# ATmega1284RFR2 device description
Architecture: AVR8; Family: megaAVR
Registers are 8-bit, access not given, no defined reset value unless marked. A register's access mark holds for its fields unless they carry their own. Offsets are from the block's base; [hi:lo] are bit positions; {n}, {i} and the like mark numbered series; <NAME> marks a mode.

## TRX24 — Low-Power 2.4 GHz Transceiver
Instances: TRX24 0x00
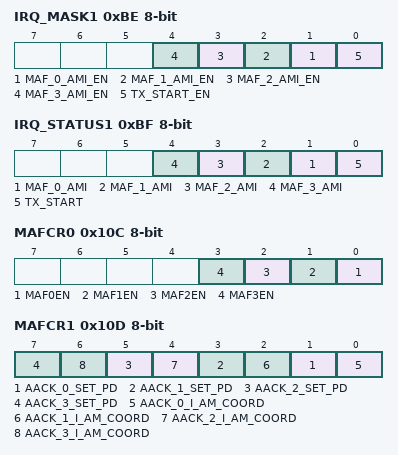
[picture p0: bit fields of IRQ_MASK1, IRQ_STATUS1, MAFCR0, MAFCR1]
0xBE IRQ_MASK1 — Transceiver Interrupt Enable Register 1
  [n+1] MAF_{n}_AMI_EN (n=0..3) — Address Match Interrupt enable Address filter {n}
  [0] TX_START_EN — Transmit Start Interrupt enable
0xBF IRQ_STATUS1 — Transceiver Interrupt Status Register 1
  [n+1] MAF_{n}_AMI (n=0..3) — Address Match Interrupt Status Address filter {n}
  [0] TX_START — Transmit Start Interrupt Status
0x10C MAFCR0 — Multiple Address Filter Configuration Register 0
  [n] MAF{n}EN (n=0..3) — Multiple Address Filter {n} Enable
0x10D MAFCR1 — Multiple Address Filter Configuration Register 1
  [2n+1] AACK_{n}_SET_PD (n=0..3) — Set Data Pending bit for address filter {n}.
  [2n] AACK_{n}_I_AM_COORD (n=0..3) — Enable PAN Coordinator mode for address filter {n}.
{0x10E+4i} MAFSA{i}L (i=0..3) — Transceiver MAC Short Address Register for Frame Filter {i} (Low Byte)
  [7:0] MAFSA{i}L — MAC Short Address low Byte for Frame Filter {i}
{0x10F+4i} MAFSA{i}H (i=0..3) — Transceiver MAC Short Address Register for Frame Filter {i} (High Byte)
  [7:0] MAFSA{i}H — MAC Short Address high Byte for Frame Filter {i}
{0x110+4i} MAFPA{i}L (i=0..3) — Transceiver Personal Area Network ID Register for Frame Filter {i} (Low Byte)
  [7:0] MAFPA{i}L — MAC Personal Area Network ID low Byte for Frame Filter {i}
{0x111+4i} MAFPA{i}H (i=0..3) — Transceiver Personal Area Network ID Register for Frame Filter {i} (High Byte)
  [7:0] MAFPA{i}H — MAC Personal Area Network ID high Byte for Frame Filter {i}
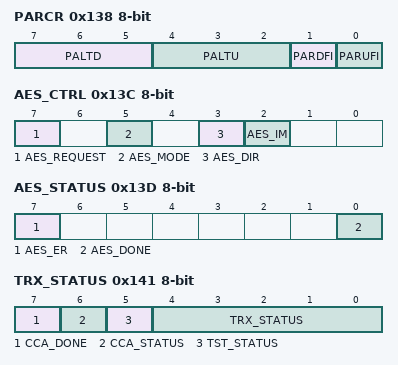
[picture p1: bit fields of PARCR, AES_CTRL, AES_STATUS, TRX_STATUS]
0x138 PARCR — Power Amplifier Ramp up/down Control Register
  [7:5] PALTD — ext. PA Ramp Down Lead Time
    0=PALTD_MINUS_3US (-3us); 1=PALTD_MINUS_2US (-2us); 2=PALTD_MINUS_1US (-1us); {v}=PALTD_{v-3}US ({v-3}us) (v=3..7)
  [4:2] PALTU — ext. PA Ramp Up Lead Time
    0=PALTU_MINUS_3US (-3us); 1=PALTU_MINUS_2US (-2us); 2=PALTU_MINUS_1US (-1us); {v}=PALTU_{v-3}US ({v-3}us) (v=3..7)
  [1] PARDFI — Power Amplifier Ramp Down Frequency Inversion
  [0] PARUFI — Power Amplifier Ramp Up Frequency Inversion
0x13C AES_CTRL — AES Control Register
  [7] AES_REQUEST — Request AES Operation.
  [5] AES_MODE — Set AES Operation Mode
    0=AES_MODE_ECB (AES Mode is ECB (Electronic Code Book).); 1=AES_MODE_CBC (AES Mode is CBC (Cipher Block Chaining).)
  [3] AES_DIR — Set AES Operation Direction
    0=AES_DIR_ENC (AES operation is encryption.); 1=AES_DIR_DEC (AES operation is decryption.)
  [2] AES_IM — AES Interrupt Enable
0x13D AES_STATUS
  [7] AES_ER — AES Operation Finished with Error
  [0] AES_DONE — AES Operation Finished with Success
0x13E AES_STATE — AES Plain and Cipher Text Buffer Register
  [7:0] AES_STATE — AES Plain and Cipher Text Buffer
0x13F AES_KEY — AES Encryption and Decryption Key Buffer Register
  [7:0] AES_KEY — AES Encryption/Decryption Key Buffer
0x141 TRX_STATUS — Transceiver Status Register
  [7] CCA_DONE — CCA Algorithm Status
    0=CCA_NOT_FIN (CCA calculation not finished); 1=CCA_FIN (CCA calculation finished)
  [6] CCA_STATUS — CCA Status Result
    0=CCA_BUSY (Channel indicated as busy.); 1=CCA_IDLE (Channel indicated as idle.)
  [5] TST_STATUS — Test mode status
    0=TST_DISABLED (Test mode is disabled.); 1=TST_ENABLED (Test mode is active.)
  [4:0] TRX_STATUS — Transceiver Main Status
    0=P_ON; 1=BUSY_RX; 2=BUSY_TX; 6=RX_ON; 8=TRX_OFF; 9=PLL_ON; 15=SLEEP; 17=BUSY_RX_AACK; 18=BUSY_TX_ARET; 22=RX_AACK_ON; 25=TX_ARET_ON; 31=STATE_TRANSITION_IN_PROGRESS
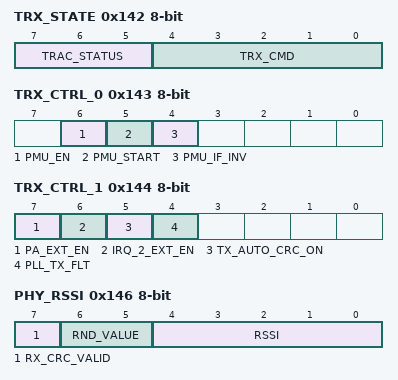
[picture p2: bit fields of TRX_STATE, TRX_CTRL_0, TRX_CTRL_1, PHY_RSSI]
0x142 TRX_STATE — Transceiver State Control Register
  [7:5] TRAC_STATUS — Transaction Status
    0=TRAC_SUCCESS (SUCCESS (RX_AACK, TX_ARET)); 1=TRAC_SUCCESS_DATA_PENDING (SUCCESS_DATA_PENDING (TX_ARET)); 2=TRAC_SUCCESS_WAIT_FOR_ACK (SUCCESS_WAIT_FOR_ACK (RX_AACK)); 3=TRAC_CHANNEL_ACCESS_FAILURE (CHANNEL_ACCESS_FAILURE (TX_ARET)); 5=TRAC_NO_ACK (NO_ACK (TX_ARET)); 7=TRAC_INVALID (INVALID (RX_AACK, TX_ARET))
  [4:0] TRX_CMD — State Control Command
    0=CMD_NOP (NOP); 2=CMD_TX_START (TX_START); 3=CMD_FORCE_TRX_OFF (FORCE_TRX_OFF); 4=CMD_FORCE_PLL_ON (FORCE_PLL_ON); 6=CMD_RX_ON (RX_ON); 8=CMD_TRX_OFF (TRX_OFF); 9=CMD_PLL_ON (PLL_ON (TX_ON)); 22=CMD_RX_AACK_ON (RX_AACK_ON); 25=CMD_TX_ARET_ON (TX_ARET_ON)
0x143 TRX_CTRL_0 — Reserved
  [6] PMU_EN — Enable Phase Measurement Unit
  [5] PMU_START — Start of Phase Measurement Unit
  [4] PMU_IF_INV — PMU IF Inverse
0x144 TRX_CTRL_1 — Transceiver Control Register 1
  [7] PA_EXT_EN — External PA support enable
  [6] IRQ_2_EXT_EN — Connect Frame Start IRQ to TC1
  [5] TX_AUTO_CRC_ON — Enable Automatic CRC Calculation
  [4] PLL_TX_FLT — Enable PLL TX filter
0x145 PHY_TX_PWR — Transceiver Transmit Power Control Register
  [3:0] TX_PWR — Transmit Power Setting
    0=3.5 dBm; 1=3.3 dBm; 2=2.8 dBm; 3=2.3 dBm; 4=1.8 dBm; 5=1.2 dBm; 6=0.5 dBm; 7=-0.5 dBm; 8=-1.5 dBm; 9=-2.5 dBm; 10=-3.5 dBm; 11=-4.5 dBm; 12=-6.5 dBm; 13=-8.5 dBm; 14=-11.5 dBm; 15=-16.5 dBm
0x146 PHY_RSSI — Receiver Signal Strength Indicator Register
  [7] RX_CRC_VALID — Received Frame CRC Status
    0=CRC_INVALID (CRC (FCS) not valid); 1=CRC_VALID (CRC (FCS) valid)
  [6:5] RND_VALUE — Random Value
  [4:0] RSSI — Receiver Signal Strength Indicator
    0=RSSI_MIN (Minimum RSSI value: P(RF) < -90 dBm); 1=RSSI_MIN_PLUS_3dB (P(RF) = RSSI_BASE_VAL+3 · (RSSI-1) [dBm]); 2=VAL_2; 28=RSSI_MAX (Maximum RSSI value: P(RF) ≥ -10 dBm)
0x147 PHY_ED_LEVEL — Transceiver Energy Detection Level Register
  [7:0] ED_LEVEL — Energy Detection Level
    0=ED_MIN (Minimum result of last ED measurement); 1=ED_MIN_PLUS_1dB (P(RF) = RSSI_BASE_VAL+ED [dBm]); 2=VAL_0x02; 84=ED_MAX (Maximum result of last ED measurement); 255=ED_RESET (Reset value)
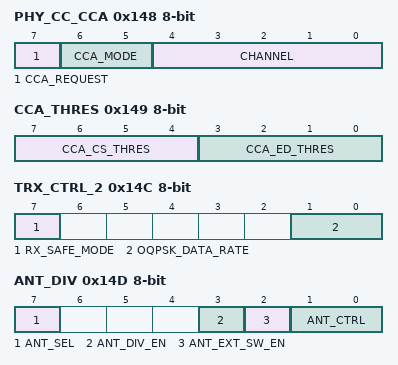
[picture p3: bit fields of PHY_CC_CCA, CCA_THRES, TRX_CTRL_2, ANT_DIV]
0x148 PHY_CC_CCA — Transceiver Clear Channel Assessment (CCA) Control Register
  [7] CCA_REQUEST — Manual CCA Measurement Request
  [6:5] CCA_MODE — Select CCA Measurement Mode
    0=CCA_CS_OR_ED (Mode 3a, Carrier sense OR energy above threshold); 1=CCA_ED (Mode 1, Energy above threshold); 2=CCA_CS (Mode 2, Carrier sense only); 3=CCA_CS_AND_ED (Mode 3b, Carrier sense AND energy above threshold)
  [4:0] CHANNEL — RX/TX Channel Selection
    11=F_2405MHZ (2405 MHz); 12=F_2410MHZ (2410 MHz); 13=F_2415MHZ (2415 MHz); 14=F_2420MHZ (2420 MHz); 15=F_2425MHZ (2425 MHz); 16=F_2430MHZ (2430 MHz); 17=F_2435MHZ (2435 MHz); 18=F_2440MHZ (2440 MHz); 19=F_2445MHZ (2445 MHz); 20=F_2450MHZ (2450 MHz); 21=F_2455MHZ (2455 MHz); 22=F_2460MHZ (2460 MHz); 23=F_2465MHZ (2465 MHz); 24=F_2470MHZ (2470 MHz); 25=F_2475MHZ (2475 MHz); 26=F_2480MHZ (2480 MHz)
0x149 CCA_THRES — Transceiver CCA Threshold Setting Register
  [7:4] CCA_CS_THRES — CS Threshold Level for CCA Measurement
  [3:0] CCA_ED_THRES — ED Threshold Level for CCA Measurement
0x14A RX_CTRL — Transceiver Receive Control Register
  [3:0] PDT_THRES — Receiver Sensitivity Control
    7=PDT_THRES_ANT_DIV_OFF (Reset value, to be used if Antenna Diversity algorithm is disabled); 3=PDT_THRES_ANT_DIV_ON (Recommended correlator threshold for Antenna Diversity operation)
0x14B SFD_VALUE — Start of Frame Delimiter Value Register
  [7:0] SFD_VALUE — Start of Frame Delimiter Value
    167=IEEE_SFD (IEEE 802.15.4 compliant value of the SFD)
0x14C TRX_CTRL_2 — Transceiver Control Register 2
  [7] RX_SAFE_MODE
  [1:0] OQPSK_DATA_RATE — Data Rate Selection
    0=RATE_250KB (250 kb/s (IEEE 802.15.4 compliant)); 1=RATE_500KB (500 kb/s); 2=RATE_1000KB (1000 kb/s); 3=RATE_2000KB (2000 kb/s)
0x14D ANT_DIV — Antenna Diversity Control Register
  [7] ANT_SEL — Antenna Diversity Antenna Status
    0=ANTENNA_0; 1=ANTENNA_1
  [3] ANT_DIV_EN — Enable Antenna Diversity
    0=Antenna Diversity algorithm disabled; 1=Antenna Diversity algorithm enabled
  [2] ANT_EXT_SW_EN — Enable External Antenna Switch Control
    0=ANT_DIV_EXT_SW_DIS (Antenna Diversity RF switch control disabled); 1=ANT_DIV_EXT_SW_EN (Antenna Diversity RF switch control enabled)
  [1:0] ANT_CTRL — Static Antenna Diversity Switch Control
    1=ANT_1 (Antenna 1: DIG1=H, DIG2=L); 2=ANT_0 (Antenna 0: DIG1=L, DIG2=H); 3=ANT_RESET (Default value for ANT_EXT_SW_EN=0; Mandatory setting for applications not using Antenna Diversity)
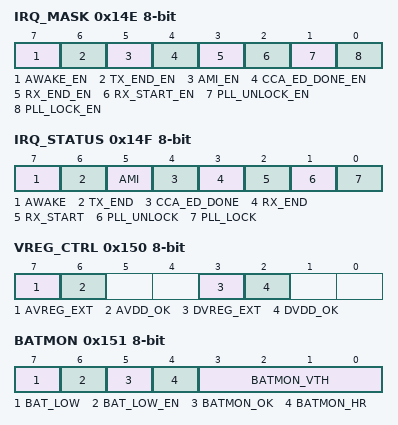
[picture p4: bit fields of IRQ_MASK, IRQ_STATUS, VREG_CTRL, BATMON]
0x14E IRQ_MASK — Transceiver Interrupt Enable Register
  [7] AWAKE_EN — Awake Interrupt Enable
  [6] TX_END_EN — TX_END Interrupt Enable
  [5] AMI_EN — Address Match Interrupt Enable
  [4] CCA_ED_DONE_EN — End of ED Measurement Interrupt Enable
  [3] RX_END_EN — RX_END Interrupt Enable
  [2] RX_START_EN — RX_START Interrupt Enable
  [1] PLL_UNLOCK_EN — PLL Unlock Interrupt Enable
  [0] PLL_LOCK_EN — PLL Lock Interrupt Enable
0x14F IRQ_STATUS — Transceiver Interrupt Status Register
  [7] AWAKE — Awake Interrupt Status
  [6] TX_END — TX_END Interrupt Status
  [5] AMI — Address Match Interrupt Status
  [4] CCA_ED_DONE — End of ED Measurement Interrupt Status
  [3] RX_END — RX_END Interrupt Status
  [2] RX_START — RX_START Interrupt Status
  [1] PLL_UNLOCK — PLL Unlock Interrupt Status
  [0] PLL_LOCK — PLL Lock Interrupt Status
0x150 VREG_CTRL — Voltage Regulator Control and Status Register
  [7] AVREG_EXT — Use External AVDD Regulator
    0=AVDD_INT (Internal AVDD voltage regulator for the analog section is enabled.); 1=AVDD_EXT (Internal AVDD voltage regulator is disabled; use external regulated 1.8V supply voltage for the analog section.)
  [6] AVDD_OK — AVDD Supply Voltage Valid
    0=Analog voltage regulator disabled or supply voltage not stable; 1=Analog supply voltage has settled
  [3] DVREG_EXT — Use External DVDD Regulator
    0=DVDD_INT (Internal DVDD voltage regulator for the digital section is enabled.); 1=DVDD_EXT (Internal DVDD voltage regulator is disabled; use external regulated 1.8V supply voltage for the digital section.)
  [2] DVDD_OK — DVDD Supply Voltage Valid
    0=Digital voltage regulator disabled or supply voltage not stable; 1=Digital supply voltage has settled
0x151 BATMON — Battery Monitor Control and Status Register
  [7] BAT_LOW — Battery Monitor Interrupt Status
  [6] BAT_LOW_EN — Battery Monitor Interrupt Enable
  [5] BATMON_OK — Battery Monitor Status
    0=The battery voltage is below the threshold; 1=The battery voltage is above the threshold
  [4] BATMON_HR — Battery Monitor Voltage Range
    0=BATMON_HR_DIS (Enables the low range, see BATMON_VTH); 1=BATMON_HR_EN (Enables the high range, see BATMON_VTH)
  [3:0] BATMON_VTH — Battery Monitor Threshold Voltage
    0=2.550V / 1.70V (BATMON_HR=1/0); 1=2.625V / 1.75V (BATMON_HR=1/0); 2=2.700V / 1.80V (BATMON_HR=1/0); 3=2.775V / 1.85V (BATMON_HR=1/0); 4=2.850V / 1.90V (BATMON_HR=1/0); 5=2.925V / 1.95V (BATMON_HR=1/0); 6=3.000V / 2.00V (BATMON_HR=1/0); 7=3.075V / 2.05V (BATMON_HR=1/0); 8=3.150V / 2.10V (BATMON_HR=1/0); 9=3.225V / 2.15V (BATMON_HR=1/0); 10=3.300V / 2.20V (BATMON_HR=1/0); 11=3.375V / 2.25V (BATMON_HR=1/0); 12=3.450V / 2.30V (BATMON_HR=1/0); 13=3.525V / 2.35V (BATMON_HR=1/0); 14=3.600V / 2.40V (BATMON_HR=1/0); 15=3.675V / 2.45V (BATMON_HR=1/0)
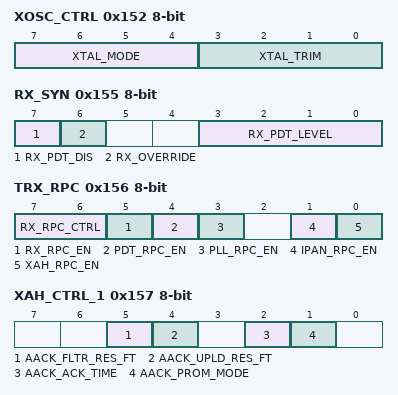
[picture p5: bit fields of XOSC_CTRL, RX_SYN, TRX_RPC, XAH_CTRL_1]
0x152 XOSC_CTRL — Crystal Oscillator Control Register
  [7:4] XTAL_MODE — Crystal Oscillator Operating Mode
    4=Internal crystal oscillator disabled; use external reference frequency; 15=Internal crystal oscillator enabled; amplitude regulation of oscillation enabled
  [3:0] XTAL_TRIM — Crystal Oscillator Load Capacitance Trimming
    0=XTAL_TRIM_MIN (0.0 pF, trimming capacitors disconnected); 1=0.3 pF, trimming capacitor switched on; 2=VAL_0x2; 15=XTAL_TRIM_MAX (4.5 pF, trimming capacitor switched on)
0x153 CC_CTRL_0 — Channel Control Register 0
  [7:0] CC_NUMBER — Channel Number
0x154 CC_CTRL_1 — Channel Control Register 1
  [3:0] CC_BAND — Channel Band
0x155 RX_SYN — Transceiver Receiver Sensitivity Control Register
  [7] RX_PDT_DIS — Prevent Frame Reception
  [6] RX_OVERRIDE — Receiver Override Function
  [3:0] RX_PDT_LEVEL — Reduce Receiver Sensitivity
    0=RX_PDT_LEVEL_MIN (RX_THRES ≤ RSSI_BASE_VAL (Reset value); RSSI value not considered); 1=RX_THRES > RSSI_BASE_VAL + 0 · 3; RSSI > -90 dBm; 2=VAL_0x2; 14=RX_THRES > RSSI_BASE_VAL + 13 · 3; RSSI > -51 dBm; 15=RX_PDT_LEVEL_MAX (RX_THRES > RSSI_BASE_VAL + 14 · 3; RSSI > -48 dBm)
0x156 TRX_RPC — Transceiver Reduced Power Consumption Control
  [7:6] RX_RPC_CTRL — Smart Receiving Mode Timing
    0=Activates minimum power saving behaviour for smart receiving mode; 3=Activates maximum power saving behaviour for smart receiving mode
  [5] RX_RPC_EN — Reciver Smart Receiving Mode Enable
  [4] PDT_RPC_EN — Smart Receiving Mode Reduced Sensitivity Enable
  [3] PLL_RPC_EN — PLL Smart Receiving Mode Enable
  [1] IPAN_RPC_EN — Smart Receiving Mode IPAN Handling Enable
  [0] XAH_RPC_EN — Smart Receiving in Extended Operating Modes Enable
0x157 XAH_CTRL_1 — Transceiver Acknowledgment Frame Control Register 1
  [5] AACK_FLTR_RES_FT — Filter Reserved Frames
  [4] AACK_UPLD_RES_FT — Process Reserved Frames
  [2] AACK_ACK_TIME — Reduce Acknowledgment Time
    0=AACK_ACK_TIME_12_SYM (12 symbols acknowledgment time); 1=AACK_ACK_TIME_2_SYM (2 symbols acknowledgment time)
  [1] AACK_PROM_MODE — Enable Promiscuous Mode
0x158 FTN_CTRL — Transceiver Filter Tuning Control Register
  [7] FTN_START — Start Calibration Loop of Filter Tuning Network
0x15A PLL_CF — Transceiver Center Frequency Calibration Control Register
  [7] PLL_CF_START — Start Center Frequency Calibration
0x15B PLL_DCU — Transceiver Delay Cell Calibration Control Register
  [7] PLL_DCU_START — Start Delay Cell Calibration
0x15C PART_NUM — Device Identification Register (Part Number)
  [7:0] PART_NUM — Part Number
    131=P_ATmega128RFA1 (ATmega128RFA1 part number); 147=P_RFA2 (RFA2 family); 148=P_RFR2 (RFR2 family)
0x15D VERSION_NUM — Device Identification Register (Version Number)
  [7:0] VERSION_NUM — Version Number
    12=REV_A (Revision A); 1=REV_B (Revision B); 3=REV_C (Revision C); 4=REV_D (Revision D)
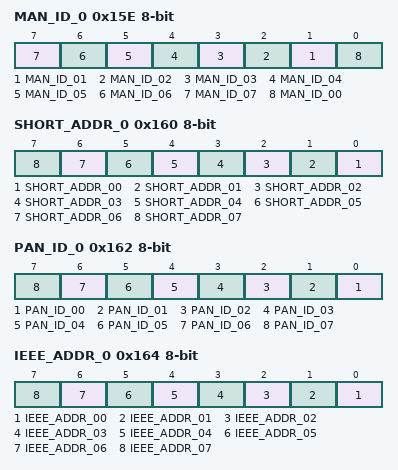
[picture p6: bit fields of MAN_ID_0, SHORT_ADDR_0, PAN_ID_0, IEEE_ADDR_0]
0x15E MAN_ID_0 — Device Identification Register (Manufacture ID Low Byte)
  [n] MAN_ID_{n:02} (n=1..7) — Manufacturer ID (Low Byte)
  [0] MAN_ID_00 — Manufacturer ID (Low Byte)
    31=ATMEL_BYTE_0 (Atmel JEDEC manufacturer ID, bits [7:0] of 32 bit manufacturer ID: 00 00 00 1F)
0x15F MAN_ID_1 — Device Identification Register (Manufacture ID High Byte)
  [7:0] MAN_ID_ (bit 10 of the value upward) — Manufacturer ID (High Byte)
    0=ATMEL_BYTE_1 (Atmel JEDEC manufacturer ID, bits [15:8] of 32 bit manufacturer ID: 00 00 00 1F)
0x160 SHORT_ADDR_0 — Transceiver MAC Short Address Register (Low Byte)
  [n] SHORT_ADDR_{n:02} (n=0..7) — MAC Short Address
0x161 SHORT_ADDR_1 — Transceiver MAC Short Address Register (High Byte)
  [7:0] SHORT_ADDR_ (bit 10 of the value upward) — MAC Short Address
0x162 PAN_ID_0 — Transceiver Personal Area Network ID Register (Low Byte)
  [n] PAN_ID_{n:02} (n=0..7) — MAC Personal Area Network ID
0x163 PAN_ID_1 — Transceiver Personal Area Network ID Register (High Byte)
  [7:0] PAN_ID_ (bit 10 of the value upward) — MAC Personal Area Network ID
0x164 IEEE_ADDR_0 — Transceiver MAC IEEE Address Register 0
  [n] IEEE_ADDR_{n:02} (n=0..7) — MAC IEEE Address
{0x164+i} IEEE_ADDR_{i} (i=1..7) — Transceiver MAC IEEE Address Register {i}
  [7:0] IEEE_ADDR_ (bit {10i} of the value upward) — MAC IEEE Address
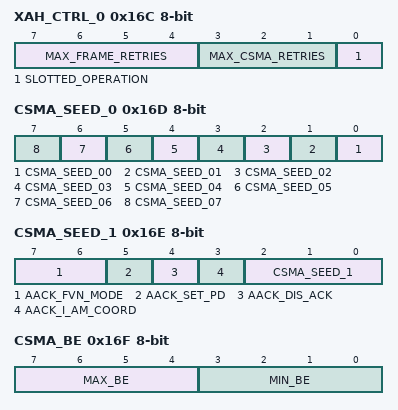
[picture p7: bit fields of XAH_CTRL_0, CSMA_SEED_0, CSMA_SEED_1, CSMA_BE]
0x16C XAH_CTRL_0 — Transceiver Extended Operating Mode Control Register
  [7:4] MAX_FRAME_RETRIES — Maximum Number of Frame Re-transmission Attempts
    0=Retransmission of frame is not attempted; 1=Retransmission of frame is attempted once; 2=VAL_0x2; 15=Retransmission of frame is attempted 15 times
  [3:1] MAX_CSMA_RETRIES — Maximum Number of CSMA-CA Procedure Repetition Attempts
    0=No repetition of CSMA-CA procedure; 1=One repetition of CSMA-CA procedure; 2=VAL_0x2; 5=Five repetitions (highest IEEE 802.15.4 compliant value); 7=Immediate frame re-transmission without performing CSMA-CA
  [0] SLOTTED_OPERATION — Set Slotted Acknowledgment
    0=SLOTTED_OP_DIS (The radio transceiver operates in unslotted mode. An acknowledgment frame is automatically sent if requested.); 1=SLOTTED_OP_EN (The transmission of an acknowledgment frame has to be controlled by the microcontroller.)
0x16D CSMA_SEED_0 — Transceiver CSMA-CA Random Number Generator Seed Register
  [n] CSMA_SEED_{n:02} (n=0..7) — Seed Value for CSMA Random Number Generator
0x16E CSMA_SEED_1 — Transceiver Acknowledgment Frame Control Register 2
  [7:6] AACK_FVN_MODE — Acknowledgment Frame Filter Mode
    0=Acknowledge frames with version number 0; 1=Acknowledge frames with version number 0 or 1; 2=Acknowledge frames with version number 0 or 1 or 2; 3=Acknowledge frames independent of frame version number
  [5] AACK_SET_PD — Set Frame Pending Sub-field
  [4] AACK_DIS_ACK — Disable Acknowledgment Frame Transmission
  [3] AACK_I_AM_COORD — Set Personal Area Network Coordinator
  [2:0] CSMA_SEED_1 — Seed Value for CSMA Random Number Generator
0x16F CSMA_BE — Transceiver CSMA-CA Back-off Exponent Control Register
  [7:4] MAX_BE — Maximum Back-off Exponent
    1=This value is not valid for the maximum back-off exponent; 2=This value is not valid for the maximum back-off exponent; 3=Minimum, IEEE compliant value for the maximum back-off exponent; 4=VAL_4; 8=Maximum, IEEE compliant value for the maximum back-off exponent
  [3:0] MIN_BE — Minimum Back-off Exponent
    0=Minimum value of minimum back-off exponent; 1=VAL_1; 8=Maximum value of minimum back-off exponent. MIN_BE must be smaller or equal to MAX_BE.
0x176 TST_CTRL_DIGI — Transceiver Digital Test Control Register
  [3:0] TST_CTRL_DIG — Digital Test Controller Register
    0=NORMAL (no test is active); 15=TST_CONT_TX (continuous transmit)
0x17B TST_RX_LENGTH — Transceiver Received Frame Length Register
  [7:0] RX_LENGTH — Received Frame Length
0x180 TRXFBST — Start of frame buffer
0x1FF TRXFBEND — End of frame buffer
